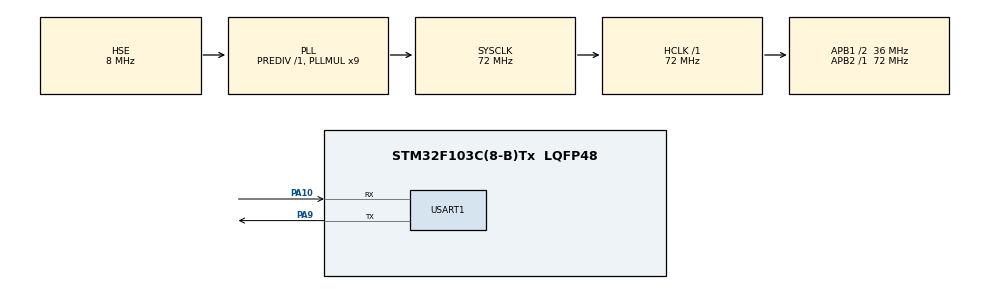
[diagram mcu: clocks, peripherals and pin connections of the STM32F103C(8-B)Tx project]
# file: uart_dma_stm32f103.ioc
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Dma.Request0=USART1_RX
Dma.USART1_RX.0.Direction=DMA_PERIPH_TO_MEMORY
Dma.USART1_RX.0.Instance=DMA1_Channel5
Dma.USART1_RX.0.MemDataAlignment=DMA_MDATAALIGN_BYTE
Dma.USART1_RX.0.MemInc=DMA_MINC_ENABLE
Dma.USART1_RX.0.Mode=DMA_NORMAL
Dma.USART1_RX.0.PeriphDataAlignment=DMA_PDATAALIGN_BYTE
Dma.USART1_RX.0.PeriphInc=DMA_PINC_DISABLE
Dma.USART1_RX.0.Priority=DMA_PRIORITY_LOW
Mcu.Family=STM32F1
Mcu.Name=STM32F103C(8-B)Tx
Mcu.Package=LQFP48
NVIC.DMA1_Channel5_IRQn=true\:0\:0\:false\:false\:true\:false\:true\:true
NVIC.PriorityGroup=NVIC_PRIORITYGROUP_4
NVIC.USART1_IRQn=true\:0\:0\:false\:false\:true\:true\:true\:true
PA10.Mode=Asynchronous
PA10.Signal=USART1_RX
PA13.Mode=Serial_Wire
PA13.Signal=SYS_JTMS-SWDIO
PA14.Mode=Serial_Wire
PA14.Signal=SYS_JTCK-SWCLK
PA9.Mode=Asynchronous
PA9.Signal=USART1_TX
PC14-OSC32_IN.Mode=LSE-External-Oscillator
PC14-OSC32_IN.Signal=RCC_OSC32_IN
PC15-OSC32_OUT.Mode=LSE-External-Oscillator
PC15-OSC32_OUT.Signal=RCC_OSC32_OUT
PD0-OSC_IN.Mode=HSE-External-Oscillator
PD0-OSC_IN.Signal=RCC_OSC_IN
PD1-OSC_OUT.Mode=HSE-External-Oscillator
PD1-OSC_OUT.Signal=RCC_OSC_OUT
ProjectManager.HeapSize=0x200
ProjectManager.StackSize=0x400
ProjectManager.TargetToolchain=STM32CubeIDE
RCC.AHBFreq_Value=72000000
RCC.APB1CLKDivider=RCC_HCLK_DIV2
RCC.APB1Freq_Value=36000000
RCC.APB1TimFreq_Value=72000000
RCC.APB2Freq_Value=72000000
RCC.APB2TimFreq_Value=72000000
RCC.HCLKFreq_Value=72000000
RCC.PLLMUL=RCC_PLL_MUL9
RCC.PLLSourceVirtual=RCC_PLLSOURCE_HSE
RCC.SYSCLKFreq_VALUE=72000000
RCC.SYSCLKSource=RCC_SYSCLKSOURCE_PLLCLK
RCC.USBFreq_Value=72000000
RTC.Date=14
RTC.Format=RTC_FORMAT_BIN
RTC.Hours=9
RTC.Minutes=35
RTC.Month=RTC_MONTH_FEBRUARY
RTC.WeekDay=RTC_WEEKDAY_TUESDAY
RTC.Year=23
USART1.VirtualMode=VM_ASYNC
VP_RTC_VS_RTC_Activate.Mode=RTC_Enabled
VP_RTC_VS_RTC_Calendar.Mode=RTC_Calendar
board=custom

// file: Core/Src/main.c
/* USER CODE BEGIN Header */
/**
 ******************************************************************************
 * @file           : main.c
 * @brief          : Main program body
 ******************************************************************************
 * @attention
 *
 * Copyright (c) 2023 STMicroelectronics.
 * All rights reserved.
 *
 * This software is licensed under terms that can be found in the LICENSE file
 * in the root directory of this software component.
 * If no LICENSE file comes with this software, it is provided AS-IS.
 *
 ******************************************************************************
 */
/* USER CODE END Header */
#include "main.h"

/* USER CODE BEGIN Includes */
#include <string.h>
#include <stdio.h>
#include <stdbool.h>
#include <stdlib.h>
#include <math.h>
/* USER CODE END Includes */

/* USER CODE BEGIN PTD */
uint8_t rxtempBuf[8];
uint8_t Buf_1ch[1];
uint8_t rxBuf[8];
uint8_t rxindex = 0;
uint8_t rxindex_2 = 0;
uint8_t rx_data[8];
uint8_t final_data[8];
uint8_t len=0;
char txdata[8];
char txdatanew[8];

char time[30];
char date[30];

/* USER CODE END PTD */

RTC_HandleTypeDef hrtc;

UART_HandleTypeDef huart1;
DMA_HandleTypeDef hdma_usart1_rx;

/* USER CODE BEGIN PV */
void sendData(char *data) {
	len = sizeof(txdata) / sizeof(txdata[0]);
	for (int i = 0; i < len; i++) {
		txdata[i] = data[i];
	}
	sprintf(txdatanew, "%s",txdata);
	HAL_UART_Transmit(&huart1, txdatanew, 8, 500);
}
/* USER CODE END PV */

void SystemClock_Config(void);
static void MX_GPIO_Init(void);
static void MX_DMA_Init(void);
static void MX_USART1_UART_Init(void);
static void MX_RTC_Init(void);

/* USER CODE BEGIN 0 */
void HAL_UART_RxCpltCallback(UART_HandleTypeDef *huart) {
	if (huart == &huart1) {

		rxBuf[rxindex] = Buf_1ch[0];
		final_data[rxindex] = rxBuf[rxindex];
		rxindex++;

		HAL_UART_Receive_DMA(&huart1, Buf_1ch, 1);
		if (rxindex >= 8) {
			rxindex = 0;
		}
	}
}

RTC_TimeTypeDef sTime;
RTC_DateTypeDef DateToUpdate;
/* USER CODE END 0 */

int main(void)
{

	/* MCU Configuration--------------------------------------------------------*/

	/* Reset of all peripherals, Initializes the Flash interface and the Systick. */
	HAL_Init();

	/* Configure the system clock */
	SystemClock_Config();

	/* Initialize all configured peripherals */
	MX_GPIO_Init();
	MX_DMA_Init();
	MX_USART1_UART_Init();
	MX_RTC_Init();
	/* USER CODE BEGIN 2 */
	HAL_UART_Receive_DMA(&huart1, Buf_1ch, 1);
	__HAL_DMA_DISABLE_IT(&hdma_usart1_rx, DMA_IT_HT);
	/* USER CODE END 2 */

	/* Infinite loop */
	while (1)
	{

		/* USER CODE BEGIN 3 */
		HAL_RTC_GetTime(&hrtc, &sTime, RTC_FORMAT_BIN);
		HAL_RTC_GetDate(&hrtc, &DateToUpdate, RTC_FORMAT_BIN);

		sprintf(date,"Date: %02d.%02d.%02d\t",DateToUpdate.Date,DateToUpdate.Month,DateToUpdate.Year);
		sprintf(time,"Time: %02d.%02d.%02d\r\n",sTime.Hours,sTime.Minutes,sTime.Seconds);
		HAL_Delay(1000);

		sendData("66666666");
		HAL_Delay(1000);
		sendData("11111111");
		HAL_Delay(1000);
		sendData("44444444");
		HAL_Delay(1000);
	}
	/* USER CODE END 3 */
}

void SystemClock_Config(void)
{
	RCC_OscInitTypeDef RCC_OscInitStruct = {0};
	RCC_ClkInitTypeDef RCC_ClkInitStruct = {0};
	RCC_PeriphCLKInitTypeDef PeriphClkInit = {0};

	/** Initializes the RCC Oscillators according to the specified parameters
	 * in the RCC_OscInitTypeDef structure.
	 */
	RCC_OscInitStruct.OscillatorType = RCC_OSCILLATORTYPE_LSI|RCC_OSCILLATORTYPE_HSE;
	RCC_OscInitStruct.HSEState = RCC_HSE_ON;
	RCC_OscInitStruct.HSEPredivValue = RCC_HSE_PREDIV_DIV1;
	RCC_OscInitStruct.HSIState = RCC_HSI_ON;
	RCC_OscInitStruct.LSIState = RCC_LSI_ON;
	RCC_OscInitStruct.PLL.PLLState = RCC_PLL_ON;
	RCC_OscInitStruct.PLL.PLLSource = RCC_PLLSOURCE_HSE;
	RCC_OscInitStruct.PLL.PLLMUL = RCC_PLL_MUL9;
	if (HAL_RCC_OscConfig(&RCC_OscInitStruct) != HAL_OK)
	{
		Error_Handler();
	}

	/** Initializes the CPU, AHB and APB buses clocks
	 */
	RCC_ClkInitStruct.ClockType = RCC_CLOCKTYPE_HCLK|RCC_CLOCKTYPE_SYSCLK
			|RCC_CLOCKTYPE_PCLK1|RCC_CLOCKTYPE_PCLK2;
	RCC_ClkInitStruct.SYSCLKSource = RCC_SYSCLKSOURCE_PLLCLK;
	RCC_ClkInitStruct.AHBCLKDivider = RCC_SYSCLK_DIV1;
	RCC_ClkInitStruct.APB1CLKDivider = RCC_HCLK_DIV2;
	RCC_ClkInitStruct.APB2CLKDivider = RCC_HCLK_DIV1;

	if (HAL_RCC_ClockConfig(&RCC_ClkInitStruct, FLASH_LATENCY_2) != HAL_OK)
	{
		Error_Handler();
	}
	PeriphClkInit.PeriphClockSelection = RCC_PERIPHCLK_RTC;
	PeriphClkInit.RTCClockSelection = RCC_RTCCLKSOURCE_LSI;
	if (HAL_RCCEx_PeriphCLKConfig(&PeriphClkInit) != HAL_OK)
	{
		Error_Handler();
	}
}

static void MX_RTC_Init(void)
{

	RTC_TimeTypeDef sTime = {0};
	RTC_DateTypeDef DateToUpdate = {0};

	/** Initialize RTC Only
	 */
	hrtc.Instance = RTC;
	hrtc.Init.AsynchPrediv = RTC_AUTO_1_SECOND;
	hrtc.Init.OutPut = RTC_OUTPUTSOURCE_ALARM;
	if (HAL_RTC_Init(&hrtc) != HAL_OK)
	{
		Error_Handler();
	}

	/** Initialize RTC and set the Time and Date
	 */
	sTime.Hours = 9;
	sTime.Minutes = 35;
	sTime.Seconds = 0;

	if (HAL_RTC_SetTime(&hrtc, &sTime, RTC_FORMAT_BIN) != HAL_OK)
	{
		Error_Handler();
	}
	DateToUpdate.WeekDay = RTC_WEEKDAY_TUESDAY;
	DateToUpdate.Month = RTC_MONTH_FEBRUARY;
	DateToUpdate.Date = 14;
	DateToUpdate.Year = 23;

	if (HAL_RTC_SetDate(&hrtc, &DateToUpdate, RTC_FORMAT_BIN) != HAL_OK)
	{
		Error_Handler();
	}

}

static void MX_USART1_UART_Init(void)
{

	huart1.Instance = USART1;
	huart1.Init.BaudRate = 115200;
	huart1.Init.WordLength = UART_WORDLENGTH_8B;
	huart1.Init.StopBits = UART_STOPBITS_1;
	huart1.Init.Parity = UART_PARITY_NONE;
	huart1.Init.Mode = UART_MODE_TX_RX;
	huart1.Init.HwFlowCtl = UART_HWCONTROL_NONE;
	huart1.Init.OverSampling = UART_OVERSAMPLING_16;
	if (HAL_UART_Init(&huart1) != HAL_OK)
	{
		Error_Handler();
	}

}

static void MX_DMA_Init(void)
{

	/* DMA controller clock enable */
	__HAL_RCC_DMA1_CLK_ENABLE();

	/* DMA interrupt init */
	/* DMA1_Channel5_IRQn interrupt configuration */
	HAL_NVIC_SetPriority(DMA1_Channel5_IRQn, 0, 0);
	HAL_NVIC_EnableIRQ(DMA1_Channel5_IRQn);

}

static void MX_GPIO_Init(void)
{

	/* GPIO Ports Clock Enable */
	__HAL_RCC_GPIOC_CLK_ENABLE();
	__HAL_RCC_GPIOD_CLK_ENABLE();
	__HAL_RCC_GPIOA_CLK_ENABLE();

}

void Error_Handler(void)
{
	__disable_irq();
	while (1)
	{
	}
}
